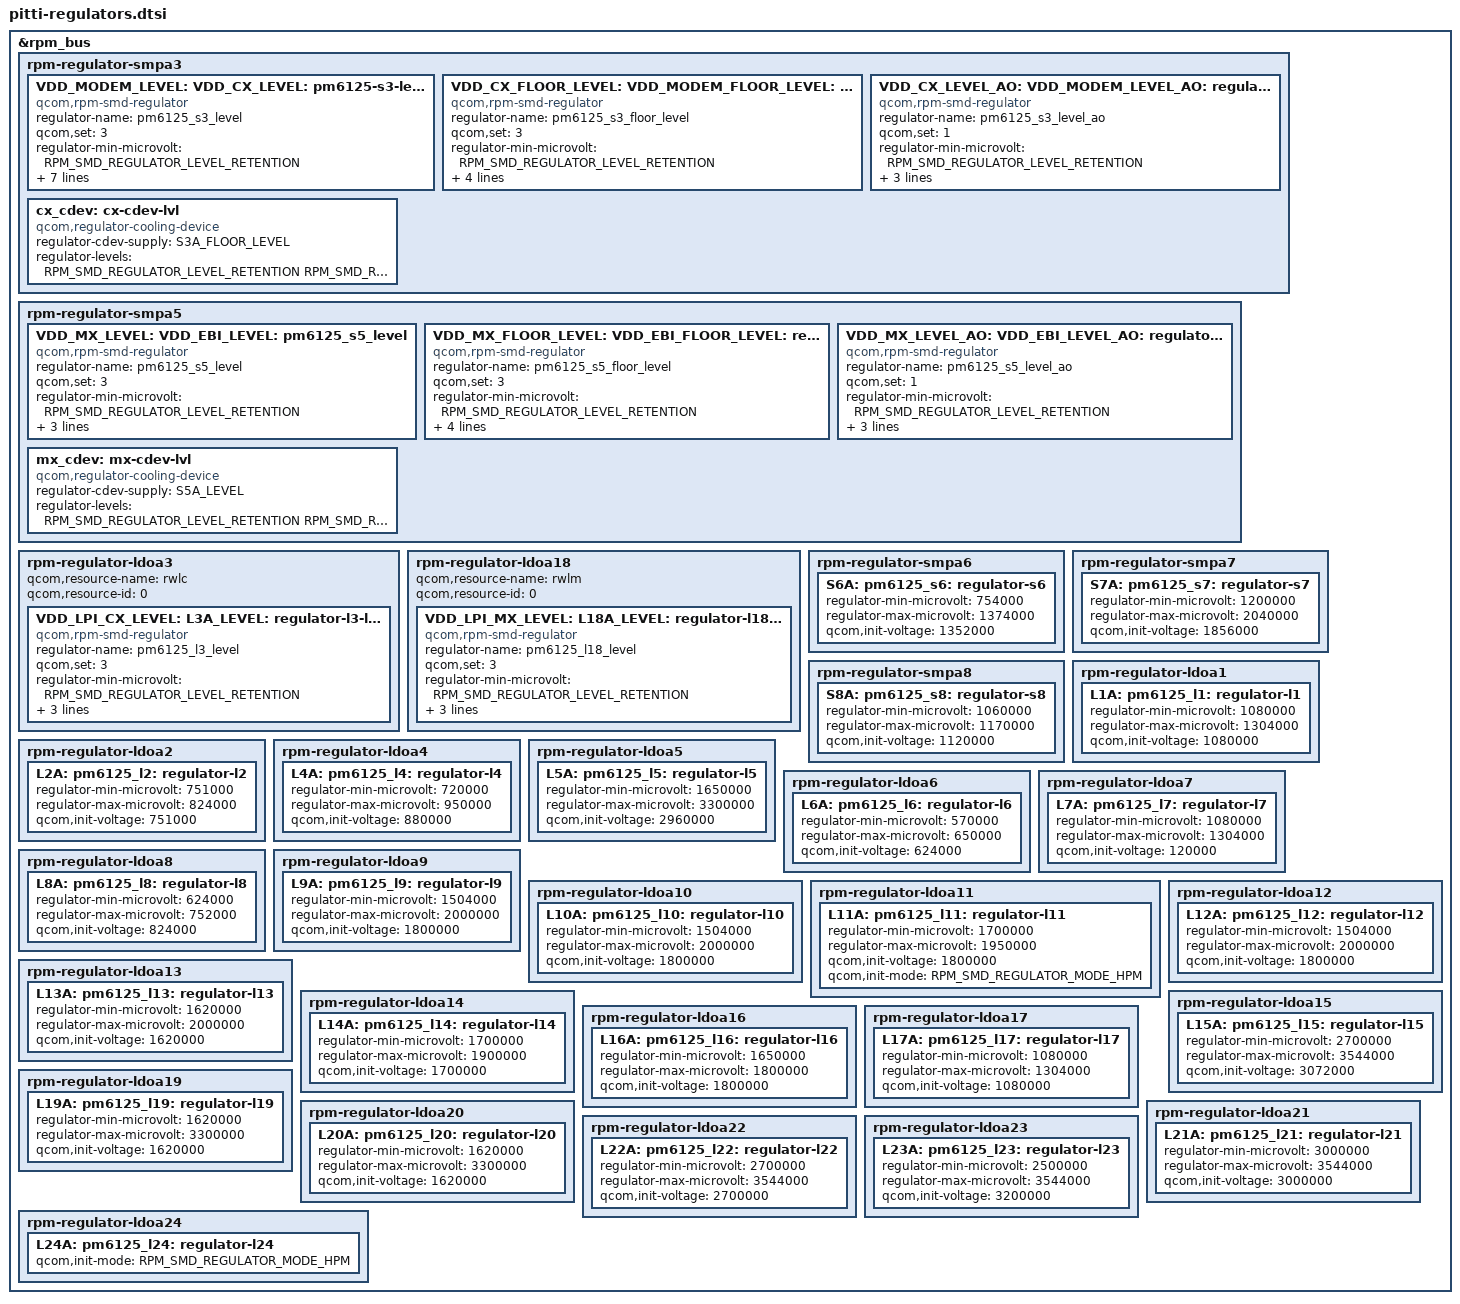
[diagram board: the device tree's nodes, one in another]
#include <dt-bindings/regulator/qcom,rpm-smd-regulator.h>
#include "pm6125-rpm-regulator.dtsi"
&rpm_bus {
	rpm-regulator-smpa3 {
		status = "okay";
		VDD_MODEM_LEVEL:
		VDD_CX_LEVEL:
		VDD_GFX_LEVEL:
		S3A_LEVEL:
		pm6125_s3_level: pm6125-s3-level {
			compatible = "qcom,rpm-smd-regulator";
			regulator-name = "pm6125_s3_level";
			qcom,set = <3>;
			regulator-min-microvolt = <RPM_SMD_REGULATOR_LEVEL_RETENTION>;
			regulator-max-microvolt = <RPM_SMD_REGULATOR_LEVEL_BINNING>;
			proxy-supply = <&pm6125_s3_level>;
			qcom,proxy-consumer-enable;
			qcom,proxy-consumer-voltage = <RPM_SMD_REGULATOR_LEVEL_TURBO
						RPM_SMD_REGULATOR_LEVEL_BINNING>;
			qcom,use-voltage-level;
		};

		VDD_CX_FLOOR_LEVEL:
		VDD_MODEM_FLOOR_LEVEL:
		VDD_GFX_FLOOR_LEVEL:
		S3A_FLOOR_LEVEL:
		pm6125_s3_floor_level: regulator-s3-floor-level {
			compatible = "qcom,rpm-smd-regulator";
			regulator-name = "pm6125_s3_floor_level";
			qcom,set = <3>;
			regulator-min-microvolt = <RPM_SMD_REGULATOR_LEVEL_RETENTION>;
			regulator-max-microvolt = <RPM_SMD_REGULATOR_LEVEL_BINNING>;
			qcom,use-voltage-floor-level;
			qcom,always-send-voltage;
		};

		VDD_CX_LEVEL_AO:
		VDD_MODEM_LEVEL_AO:
		VDD_GFX_FLOOR_LEVEL_AO:
		S3A_LEVEL_AO: pm6125_s3_level_ao: regulator-s3-level-ao {
			compatible = "qcom,rpm-smd-regulator";
			regulator-name = "pm6125_s3_level_ao";
			qcom,set = <1>;
			regulator-min-microvolt =
				<RPM_SMD_REGULATOR_LEVEL_RETENTION>;
			regulator-max-microvolt =
				<RPM_SMD_REGULATOR_LEVEL_BINNING>;
			qcom,use-voltage-level;
		};

		cx_cdev: cx-cdev-lvl {
			status = "okay";
			compatible = "qcom,regulator-cooling-device";
			regulator-cdev-supply = <&S3A_FLOOR_LEVEL>;
			regulator-levels = <RPM_SMD_REGULATOR_LEVEL_RETENTION
					RPM_SMD_REGULATOR_LEVEL_SVS_PLUS>;
			#cooling-cells = <2>;
		};
	};

	rpm-regulator-smpa5 {
		status = "okay";
		VDD_MX_LEVEL:
		VDD_EBI_LEVEL:
		S5A_LEVEL:
		pm6125_s5_level: pm6125_s5_level {
			compatible = "qcom,rpm-smd-regulator";
			regulator-name = "pm6125_s5_level";
			qcom,set = <3>;
			regulator-min-microvolt = <RPM_SMD_REGULATOR_LEVEL_RETENTION>;
			regulator-max-microvolt = <RPM_SMD_REGULATOR_LEVEL_BINNING>;
			qcom,use-voltage-level;
		};

		VDD_MX_FLOOR_LEVEL:
		VDD_EBI_FLOOR_LEVEL:
		S5A_FLOOR_LEVEL:
		pm6125_s5_floor_level: regulator-s5-floor-level {
			compatible = "qcom,rpm-smd-regulator";
			regulator-name = "pm6125_s5_floor_level";
			qcom,set = <3>;
			regulator-min-microvolt = <RPM_SMD_REGULATOR_LEVEL_RETENTION>;
			regulator-max-microvolt = <RPM_SMD_REGULATOR_LEVEL_BINNING>;
			qcom,use-voltage-floor-level;
			qcom,always-send-voltage;
		};

		VDD_MX_LEVEL_AO:
		VDD_EBI_LEVEL_AO:
		S5A_LEVEL_AO: pm6125_s5_level_ao: regulator-s5-level-ao {
			compatible = "qcom,rpm-smd-regulator";
			regulator-name = "pm6125_s5_level_ao";
			qcom,set = <1>;
			regulator-min-microvolt =
				<RPM_SMD_REGULATOR_LEVEL_RETENTION>;
			regulator-max-microvolt =
				<RPM_SMD_REGULATOR_LEVEL_BINNING>;
			qcom,use-voltage-level;
		};

		mx_cdev: mx-cdev-lvl {
			status = "okay";
			compatible = "qcom,regulator-cooling-device";
			regulator-cdev-supply = <&S5A_LEVEL>;
			regulator-levels = <RPM_SMD_REGULATOR_LEVEL_RETENTION
					RPM_SMD_REGULATOR_LEVEL_SVS_PLUS>;
			#cooling-cells = <2>;
		};
	};


	rpm-regulator-ldoa3 {
		status = "okay";
		qcom,resource-name = "rwlc";
		qcom,resource-id = <0>;
		VDD_LPI_CX_LEVEL:
		L3A_LEVEL:
		pm6125_l3_level: regulator-l3-level {
			compatible = "qcom,rpm-smd-regulator";
			regulator-name = "pm6125_l3_level";
			qcom,set = <3>;
			regulator-min-microvolt = <RPM_SMD_REGULATOR_LEVEL_RETENTION>;
			regulator-max-microvolt = <RPM_SMD_REGULATOR_LEVEL_BINNING>;
			qcom,use-voltage-level;
		};
	};

	rpm-regulator-ldoa18 {
		status = "okay";
		qcom,resource-name = "rwlm";
		qcom,resource-id = <0>;
		VDD_LPI_MX_LEVEL:
		L18A_LEVEL:
		pm6125_l18_level: regulator-l18-level {
			compatible = "qcom,rpm-smd-regulator";
			regulator-name = "pm6125_l18_level";
			qcom,set = <3>;
			regulator-min-microvolt =
				<RPM_SMD_REGULATOR_LEVEL_RETENTION>;
			regulator-max-microvolt = <RPM_SMD_REGULATOR_LEVEL_BINNING>;
			qcom,use-voltage-level;
		};
	};

	rpm-regulator-smpa6 {
		status = "okay";
		S6A: pm6125_s6: regulator-s6 {
			regulator-min-microvolt = <754000>;
			regulator-max-microvolt = <1374000>;
			qcom,init-voltage = <1352000>;
			status = "okay";
		};
	};

	rpm-regulator-smpa7 {
		status = "okay";
		S7A: pm6125_s7: regulator-s7 {
			regulator-min-microvolt = <1200000>;
			regulator-max-microvolt = <2040000>;
			qcom,init-voltage = <1856000>;
			status = "okay";
		};
	};

	rpm-regulator-smpa8 {
		status = "okay";
		S8A: pm6125_s8: regulator-s8 {
			regulator-min-microvolt = <1060000>;
			regulator-max-microvolt = <1170000>;
			qcom,init-voltage = <1120000>;
			status = "okay";
		};
	};

	rpm-regulator-ldoa1 {
		status = "okay";
		L1A: pm6125_l1: regulator-l1 {
			regulator-min-microvolt = <1080000>;
			regulator-max-microvolt = <1304000>;
			qcom,init-voltage = <1080000>;
			status = "okay";
		};
	};

	rpm-regulator-ldoa2 {
		status = "okay";
		L2A: pm6125_l2: regulator-l2 {
			regulator-min-microvolt = <751000>;
			regulator-max-microvolt = <824000>;
			qcom,init-voltage = <751000>;
			status = "okay";
		};
	};

	rpm-regulator-ldoa4 {
		status = "okay";
		L4A: pm6125_l4: regulator-l4 {
			regulator-min-microvolt = <720000>;
			regulator-max-microvolt = <950000>;
			qcom,init-voltage = <880000>;
			status = "okay";
		};
	};

	rpm-regulator-ldoa5 {
		status = "okay";
		L5A: pm6125_l5: regulator-l5 {
			regulator-min-microvolt = <1650000>;
			regulator-max-microvolt = <3300000>;
			qcom,init-voltage = <2960000>;
			status = "okay";
		};
	};

	rpm-regulator-ldoa6 {
		status = "okay";
		L6A: pm6125_l6: regulator-l6 {
			regulator-min-microvolt = <570000>;
			regulator-max-microvolt = <650000>;
			qcom,init-voltage = <624000>;
			status = "okay";
		};
	};


	rpm-regulator-ldoa7 {
		status = "okay";
		L7A: pm6125_l7: regulator-l7 {
			regulator-min-microvolt = <1080000>;
			regulator-max-microvolt = <1304000>;
			qcom,init-voltage = <120000>;
			status = "okay";
		};
	};

	rpm-regulator-ldoa8 {
		status = "okay";
		L8A: pm6125_l8: regulator-l8 {
			regulator-min-microvolt = <624000>;
			regulator-max-microvolt = <752000>;
			qcom,init-voltage = <824000>;
			status = "okay";
		};
	};

	rpm-regulator-ldoa9 {
		status = "okay";
		L9A: pm6125_l9: regulator-l9 {
			regulator-min-microvolt = <1504000>;
			regulator-max-microvolt = <2000000>;
			qcom,init-voltage = <1800000>;
			status = "okay";
		};
	};

	rpm-regulator-ldoa10 {
		status = "okay";
		L10A:pm6125_l10: regulator-l10 {
			regulator-min-microvolt = <1504000>;
			regulator-max-microvolt = <2000000>;
			qcom,init-voltage = <1800000>;
			status = "okay";
		};
	};


	rpm-regulator-ldoa11 {
		status = "okay";
		L11A: pm6125_l11: regulator-l11 {
			status = "okay";
			regulator-min-microvolt = <1700000>;
			regulator-max-microvolt = <1950000>;
			qcom,init-voltage = <1800000>;
			qcom,init-mode = <RPM_SMD_REGULATOR_MODE_HPM>;
		};
	};

	rpm-regulator-ldoa12 {
		status = "okay";
		L12A: pm6125_l12: regulator-l12 {
			regulator-min-microvolt = <1504000>;
			regulator-max-microvolt = <2000000>;
			qcom,init-voltage = <1800000>;
			status = "okay";
		};
	};

	rpm-regulator-ldoa13 {
		status = "okay";
		L13A: pm6125_l13: regulator-l13 {
			regulator-min-microvolt = <1620000>;
			regulator-max-microvolt = <2000000>;
			qcom,init-voltage = <1620000>;
			status = "okay";
		};
	};

	rpm-regulator-ldoa14 {
		status = "okay";
		L14A: pm6125_l14: regulator-l14 {
			regulator-min-microvolt = <1700000>;
			regulator-max-microvolt = <1900000>;
			qcom,init-voltage = <1700000>;
			status = "okay";
		};
	};

	rpm-regulator-ldoa15 {
		status = "okay";
		L15A: pm6125_l15: regulator-l15 {
			regulator-min-microvolt = <2700000>;
			regulator-max-microvolt = <3544000>;
			qcom,init-voltage = <3072000>;
			status = "okay";
		};
	};

	rpm-regulator-ldoa16 {
		status = "okay";
		L16A: pm6125_l16: regulator-l16 {
			regulator-min-microvolt = <1650000>;
			regulator-max-microvolt = <1800000>;
			qcom,init-voltage = <1800000>;
			status = "okay";
		};
	};

	rpm-regulator-ldoa17 {
		status = "okay";
		L17A: pm6125_l17: regulator-l17 {
			regulator-min-microvolt = <1080000>;
			regulator-max-microvolt = <1304000>;
			qcom,init-voltage = <1080000>;
			status = "okay";
		};
	};

	rpm-regulator-ldoa19 {
		status = "okay";
		L19A: pm6125_l19: regulator-l19 {
			regulator-min-microvolt = <1620000>;
			regulator-max-microvolt = <3300000>;
			qcom,init-voltage = <1620000>;
			status = "okay";
		};
	};

	rpm-regulator-ldoa20 {
		status = "okay";
		L20A: pm6125_l20: regulator-l20 {
			regulator-min-microvolt = <1620000>;
			regulator-max-microvolt = <3300000>;
			qcom,init-voltage = <1620000>;
			status = "okay";
		};
	};

	rpm-regulator-ldoa21 {
		status = "okay";
		L21A: pm6125_l21: regulator-l21 {
			regulator-min-microvolt = <3000000>;
			regulator-max-microvolt = <3544000>;
			qcom,init-voltage = <3000000>;
			status = "okay";
		};
	};

	rpm-regulator-ldoa22 {
		status = "okay";
		L22A: pm6125_l22: regulator-l22 {
			regulator-min-microvolt = <2700000>;
			regulator-max-microvolt = <3544000>;
			qcom,init-voltage = <2700000>;
			status = "okay";
		};
	};

	rpm-regulator-ldoa23 {
		status = "okay";
		L23A: pm6125_l23: regulator-l23 {
			regulator-min-microvolt = <2500000>;
			regulator-max-microvolt = <3544000>;
			qcom,init-voltage = <3200000>;
			status = "okay";
		};
	};

	rpm-regulator-ldoa24 {
		status = "okay";

		/*
		 * This is for VCCQ2 UFS Peripheral,which supports 2 variants
		 * UFS 3.1 ,and UFS 2.2 both require different voltages.
		 * Hence providing as per recommendation from ufs team
		 * in various platform specific files.
		 */
		L24A: pm6125_l24: regulator-l24 {
			status = "okay";
			qcom,init-mode = <RPM_SMD_REGULATOR_MODE_HPM>;
		};
	};
};
